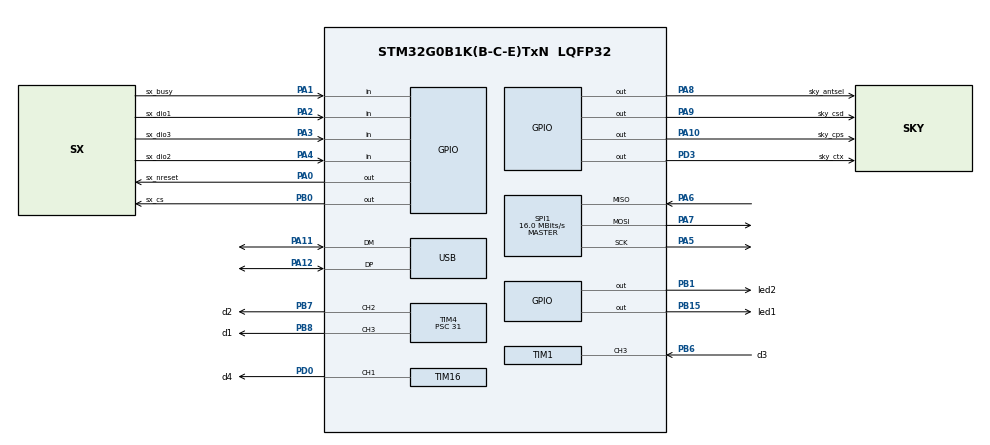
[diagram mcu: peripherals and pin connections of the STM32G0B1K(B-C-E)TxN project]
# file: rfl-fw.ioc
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IWDG.Prescaler=IWDG_PRESCALER_32
IWDG.Reload=1000
IWDG.Window=1000
Mcu.Family=STM32G0
Mcu.Name=STM32G0B1K(B-C-E)TxN
Mcu.Package=LQFP32
NVIC.TIM1_CC_IRQn=true\:0\:0\:false\:false\:false\:true\:true\:true
NVIC.USB_UCPD1_2_IRQn=true\:0\:0\:false\:false\:true\:true\:true\:true
PA0.GPIO_Label=sx_nreset
PA0.Signal=GPIO_Output
PA1.GPIO_Label=sx_busy
PA1.Signal=GPIO_Input
PA10.GPIO_Label=sky_cps
PA10.Signal=GPIO_Output
PA11\ [PA9].Mode=Device
PA11\ [PA9].Signal=USB_DM
PA12\ [PA10].Mode=Device
PA12\ [PA10].Signal=USB_DP
PA13.Mode=Serial_Wire
PA13.Signal=SYS_SWDIO
PA14-BOOT0.Mode=Serial_Wire
PA14-BOOT0.Signal=SYS_SWCLK
PA2.GPIO_Label=sx_dio1
PA2.Signal=GPIO_Input
PA3.GPIO_Label=sx_dio3
PA3.Signal=GPIO_Input
PA4.GPIO_Label=sx_dio2
PA4.Signal=GPIO_Input
PA5.Mode=Full_Duplex_Master
PA5.Signal=SPI1_SCK
PA6.Mode=Full_Duplex_Master
PA6.Signal=SPI1_MISO
PA7.Mode=Full_Duplex_Master
PA7.Signal=SPI1_MOSI
PA8.GPIO_Label=sky_antsel
PA8.Signal=GPIO_Output
PA9.GPIO_Label=sky_csd
PA9.Signal=GPIO_Output
PB0.GPIO_Label=sx_cs
PB0.Signal=GPIO_Output
PB1.GPIO_Label=led2
PB1.Signal=GPIO_Output
PB15.GPIO_Label=led1
PB15.Signal=GPIO_Output
PB6.GPIO_Label=d3
PB6.GPIO_PuPd=GPIO_PULLUP
PB6.Signal=S_TIM1_CH3
PB7.GPIO_Label=d2
PB7.Signal=S_TIM4_CH2
PB8.GPIO_Label=d1
PB8.Signal=S_TIM4_CH3
PD0.GPIO_Label=d4
PD0.Signal=S_TIM16_CH1
PD3.GPIO_Label=sky_ctx
PD3.Signal=GPIO_Output
ProjectManager.HeapSize=0x200
ProjectManager.StackSize=0x400
ProjectManager.TargetToolchain=STM32CubeIDE
RCC.ADCFreq_Value=32000000
RCC.AHBFreq_Value=32000000
RCC.CortexFreq_Value=32000000
RCC.EXTERNAL_CLOCK_VALUE=48000
RCC.HCLKFreq_Value=32000000
RCC.HSE_VALUE=8000000
RCC.HSI48_VALUE=48000000
RCC.HSI_VALUE=16000000
RCC.LSE_VALUE=32768
RCC.PLLR=RCC_PLLR_DIV4
RCC.SYSCLKFreq_VALUE=32000000
RCC.SYSCLKSource=RCC_SYSCLKSOURCE_PLLCLK
RCC.USBFreq_Value=48000000
RCC.VCOOutputFreq_Value=128000000
SH.S_TIM16_CH1.0=TIM16_CH1,PWM Generation1 CH1
SH.S_TIM1_CH3.0=TIM1_CH3,Input_Capture3_from_TI3
SH.S_TIM4_CH2.0=TIM4_CH2,PWM Generation2 CH2
SH.S_TIM4_CH3.0=TIM4_CH3,PWM Generation3 CH3
SPI1.CalculateBaudRate=16.0 MBits/s
SPI1.Direction=SPI_DIRECTION_2LINES
SPI1.Mode=SPI_MODE_MASTER
SPI1.VirtualType=VM_MASTER
TIM1.Channel-Input_Capture3_from_TI3=TIM_CHANNEL_3
TIM1.ICFilter_CH3=4
TIM1.Period=0xffff
TIM1.Prescaler=31
TIM16.AutomaticOutput=TIM_AUTOMATICOUTPUT_ENABLE
TIM16.Channel=TIM_CHANNEL_1
TIM16.Period=20000
TIM16.Prescaler=31
TIM4.Channel-PWM\ Generation2\ CH2=TIM_CHANNEL_2
TIM4.Channel-PWM\ Generation3\ CH3=TIM_CHANNEL_3
TIM4.Period=20000
TIM4.Prescaler=31
USB_DEVICE.CLASS_NAME_FS=CDC
USB_DEVICE.PRODUCT_STRING_CDC_FS=rfl
USB_DEVICE.VirtualMode=Cdc
USB_DEVICE.VirtualModeFS=Cdc_FS
VP_IWDG_VS_IWDG.Mode=IWDG_Activate
VP_SYS_VS_DBSignals.Mode=DisableDeadBatterySignals
VP_TIM16_VS_ClockSourceINT.Mode=Enable_Timer
VP_TIM1_VS_ClockSourceINT.Mode=Internal
VP_TIM4_VS_ClockSourceINT.Mode=Internal
VP_USB_DEVICE_VS_USB_DEVICE_CDC_FS.Mode=CDC_FS
board=custom

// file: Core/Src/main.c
/* USER CODE BEGIN Header */
/**
  ******************************************************************************
  * @file           : main.c
  * @brief          : Main program body
  ******************************************************************************
  * @attention
  *
  * Copyright (c) 2026 STMicroelectronics.
  * All rights reserved.
  *
  * This software is licensed under terms that can be found in the LICENSE file
  * in the root directory of this software component.
  * If no LICENSE file comes with this software, it is provided AS-IS.
  *
  ******************************************************************************
  */
/* USER CODE END Header */
#include "main.h"
#include "usb_device.h"

void SystemClock_Config(void);
static void MX_GPIO_Init(void);
static void MX_SPI1_Init(void);
static void MX_TIM1_Init(void);
static void MX_TIM4_Init(void);
static void MX_TIM16_Init(void);
static void MX_IWDG_Init(void);

/* USER CODE BEGIN 0 */
void init()
{
  HAL_Init();
  SystemClock_Config();

  MX_GPIO_Init();
  MX_SPI1_Init();
  MX_TIM1_Init();
  MX_TIM4_Init();
  MX_TIM16_Init();
  MX_IWDG_Init();
  MX_USB_Device_Init();
}
/* USER CODE END 0 */

void SystemClock_Config(void)
{
  LL_FLASH_SetLatency(LL_FLASH_LATENCY_1);
  while(LL_FLASH_GetLatency() != LL_FLASH_LATENCY_1)
  {
  }

  /* HSI configuration and activation */
  LL_RCC_HSI_Enable();
  while(LL_RCC_HSI_IsReady() != 1)
  {
  }

  /* LSI configuration and activation */
  LL_RCC_LSI_Enable();
  while(LL_RCC_LSI_IsReady() != 1)
  {
  }

  LL_RCC_HSI48_Enable();

   /* Wait till HSI48 is ready */
  while(LL_RCC_HSI48_IsReady() != 1)
  {
  }

  /* Main PLL configuration and activation */
  LL_RCC_PLL_ConfigDomain_SYS(LL_RCC_PLLSOURCE_HSI, LL_RCC_PLLM_DIV_1, 8, LL_RCC_PLLR_DIV_4);
  LL_RCC_PLL_Enable();
  LL_RCC_PLL_EnableDomain_SYS();
  while(LL_RCC_PLL_IsReady() != 1)
  {
  }

  /* Set AHB prescaler*/
  LL_RCC_SetAHBPrescaler(LL_RCC_SYSCLK_DIV_1);

  /* Sysclk activation on the main PLL */
  LL_RCC_SetSysClkSource(LL_RCC_SYS_CLKSOURCE_PLL);
  while(LL_RCC_GetSysClkSource() != LL_RCC_SYS_CLKSOURCE_STATUS_PLL)
  {
  }

  /* Set APB1 prescaler*/
  LL_RCC_SetAPB1Prescaler(LL_RCC_APB1_DIV_1);
  /* Update CMSIS variable (which can be updated also through SystemCoreClockUpdate function) */
  LL_SetSystemCoreClock(32000000);

   /* Update the time base */
  if (HAL_InitTick (TICK_INT_PRIORITY) != HAL_OK)
  {
    Error_Handler();
  }
}

static void MX_IWDG_Init(void)
{

  LL_IWDG_Enable(IWDG);
  LL_IWDG_EnableWriteAccess(IWDG);
  LL_IWDG_SetPrescaler(IWDG, LL_IWDG_PRESCALER_32);
  LL_IWDG_SetReloadCounter(IWDG, 1000);
  while (LL_IWDG_IsReady(IWDG) != 1)
  {
  }

  LL_IWDG_SetWindow(IWDG, 1000);

}

static void MX_SPI1_Init(void)
{

  LL_SPI_InitTypeDef SPI_InitStruct = {0};

  LL_GPIO_InitTypeDef GPIO_InitStruct = {0};

  /* Peripheral clock enable */
  LL_APB2_GRP1_EnableClock(LL_APB2_GRP1_PERIPH_SPI1);

  LL_IOP_GRP1_EnableClock(LL_IOP_GRP1_PERIPH_GPIOA);
  /**SPI1 GPIO Configuration
  PA5   ------> SPI1_SCK
  PA6   ------> SPI1_MISO
  PA7   ------> SPI1_MOSI
  */
  GPIO_InitStruct.Pin = LL_GPIO_PIN_5;
  GPIO_InitStruct.Mode = LL_GPIO_MODE_ALTERNATE;
  GPIO_InitStruct.Speed = LL_GPIO_SPEED_FREQ_LOW;
  GPIO_InitStruct.OutputType = LL_GPIO_OUTPUT_PUSHPULL;
  GPIO_InitStruct.Pull = LL_GPIO_PULL_NO;
  GPIO_InitStruct.Alternate = LL_GPIO_AF_0;
  LL_GPIO_Init(GPIOA, &GPIO_InitStruct);

  GPIO_InitStruct.Pin = LL_GPIO_PIN_6;
  GPIO_InitStruct.Mode = LL_GPIO_MODE_ALTERNATE;
  GPIO_InitStruct.Speed = LL_GPIO_SPEED_FREQ_LOW;
  GPIO_InitStruct.OutputType = LL_GPIO_OUTPUT_PUSHPULL;
  GPIO_InitStruct.Pull = LL_GPIO_PULL_NO;
  GPIO_InitStruct.Alternate = LL_GPIO_AF_0;
  LL_GPIO_Init(GPIOA, &GPIO_InitStruct);

  GPIO_InitStruct.Pin = LL_GPIO_PIN_7;
  GPIO_InitStruct.Mode = LL_GPIO_MODE_ALTERNATE;
  GPIO_InitStruct.Speed = LL_GPIO_SPEED_FREQ_LOW;
  GPIO_InitStruct.OutputType = LL_GPIO_OUTPUT_PUSHPULL;
  GPIO_InitStruct.Pull = LL_GPIO_PULL_NO;
  GPIO_InitStruct.Alternate = LL_GPIO_AF_0;
  LL_GPIO_Init(GPIOA, &GPIO_InitStruct);

  /* SPI1 parameter configuration*/
  SPI_InitStruct.TransferDirection = LL_SPI_FULL_DUPLEX;
  SPI_InitStruct.Mode = LL_SPI_MODE_MASTER;
  SPI_InitStruct.DataWidth = LL_SPI_DATAWIDTH_8BIT;
  SPI_InitStruct.ClockPolarity = LL_SPI_POLARITY_LOW;
  SPI_InitStruct.ClockPhase = LL_SPI_PHASE_1EDGE;
  SPI_InitStruct.NSS = LL_SPI_NSS_SOFT;
  SPI_InitStruct.BaudRate = LL_SPI_BAUDRATEPRESCALER_DIV2;
  SPI_InitStruct.BitOrder = LL_SPI_MSB_FIRST;
  SPI_InitStruct.CRCCalculation = LL_SPI_CRCCALCULATION_DISABLE;
  SPI_InitStruct.CRCPoly = 7;
  LL_SPI_Init(SPI1, &SPI_InitStruct);
  LL_SPI_SetStandard(SPI1, LL_SPI_PROTOCOL_MOTOROLA);
  LL_SPI_EnableNSSPulseMgt(SPI1);

}

static void MX_TIM1_Init(void)
{

  LL_TIM_InitTypeDef TIM_InitStruct = {0};

  LL_GPIO_InitTypeDef GPIO_InitStruct = {0};

  LL_RCC_SetTIMClockSource(LL_RCC_TIM1_CLKSOURCE_PCLK1);

  /* Peripheral clock enable */
  LL_APB2_GRP1_EnableClock(LL_APB2_GRP1_PERIPH_TIM1);

  LL_IOP_GRP1_EnableClock(LL_IOP_GRP1_PERIPH_GPIOB);
  /**TIM1 GPIO Configuration
  PB6   ------> TIM1_CH3
  */
  GPIO_InitStruct.Pin = d3_Pin;
  GPIO_InitStruct.Mode = LL_GPIO_MODE_ALTERNATE;
  GPIO_InitStruct.Speed = LL_GPIO_SPEED_FREQ_LOW;
  GPIO_InitStruct.OutputType = LL_GPIO_OUTPUT_PUSHPULL;
  GPIO_InitStruct.Pull = LL_GPIO_PULL_UP;
  GPIO_InitStruct.Alternate = LL_GPIO_AF_1;
  LL_GPIO_Init(d3_GPIO_Port, &GPIO_InitStruct);

  /* TIM1 interrupt Init */
  NVIC_SetPriority(TIM1_CC_IRQn, 0);
  NVIC_EnableIRQ(TIM1_CC_IRQn);

  TIM_InitStruct.Prescaler = 31;
  TIM_InitStruct.CounterMode = LL_TIM_COUNTERMODE_UP;
  TIM_InitStruct.Autoreload = 0xffff;
  TIM_InitStruct.ClockDivision = LL_TIM_CLOCKDIVISION_DIV1;
  TIM_InitStruct.RepetitionCounter = 0;
  LL_TIM_Init(TIM1, &TIM_InitStruct);
  LL_TIM_DisableARRPreload(TIM1);
  LL_TIM_SetClockSource(TIM1, LL_TIM_CLOCKSOURCE_INTERNAL);
  LL_TIM_SetTriggerOutput(TIM1, LL_TIM_TRGO_RESET);
  LL_TIM_SetTriggerOutput2(TIM1, LL_TIM_TRGO2_RESET);
  LL_TIM_DisableMasterSlaveMode(TIM1);
  LL_TIM_IC_SetActiveInput(TIM1, LL_TIM_CHANNEL_CH3, LL_TIM_ACTIVEINPUT_DIRECTTI);
  LL_TIM_IC_SetPrescaler(TIM1, LL_TIM_CHANNEL_CH3, LL_TIM_ICPSC_DIV1);
  LL_TIM_IC_SetFilter(TIM1, LL_TIM_CHANNEL_CH3, LL_TIM_IC_FILTER_FDIV2_N6);
  LL_TIM_IC_SetPolarity(TIM1, LL_TIM_CHANNEL_CH3, LL_TIM_IC_POLARITY_RISING);

}

static void MX_TIM4_Init(void)
{

  LL_TIM_InitTypeDef TIM_InitStruct = {0};
  LL_TIM_OC_InitTypeDef TIM_OC_InitStruct = {0};

  LL_GPIO_InitTypeDef GPIO_InitStruct = {0};

  /* Peripheral clock enable */
  LL_APB1_GRP1_EnableClock(LL_APB1_GRP1_PERIPH_TIM4);

  TIM_InitStruct.Prescaler = 31;
  TIM_InitStruct.CounterMode = LL_TIM_COUNTERMODE_UP;
  TIM_InitStruct.Autoreload = 20000;
  TIM_InitStruct.ClockDivision = LL_TIM_CLOCKDIVISION_DIV1;
  LL_TIM_Init(TIM4, &TIM_InitStruct);
  LL_TIM_DisableARRPreload(TIM4);
  LL_TIM_SetClockSource(TIM4, LL_TIM_CLOCKSOURCE_INTERNAL);
  LL_TIM_OC_EnablePreload(TIM4, LL_TIM_CHANNEL_CH2);
  TIM_OC_InitStruct.OCMode = LL_TIM_OCMODE_PWM1;
  TIM_OC_InitStruct.OCState = LL_TIM_OCSTATE_DISABLE;
  TIM_OC_InitStruct.OCNState = LL_TIM_OCSTATE_DISABLE;
  TIM_OC_InitStruct.CompareValue = 0;
  TIM_OC_InitStruct.OCPolarity = LL_TIM_OCPOLARITY_HIGH;
  LL_TIM_OC_Init(TIM4, LL_TIM_CHANNEL_CH2, &TIM_OC_InitStruct);
  LL_TIM_OC_DisableFast(TIM4, LL_TIM_CHANNEL_CH2);
  LL_TIM_OC_EnablePreload(TIM4, LL_TIM_CHANNEL_CH3);
  LL_TIM_OC_Init(TIM4, LL_TIM_CHANNEL_CH3, &TIM_OC_InitStruct);
  LL_TIM_OC_DisableFast(TIM4, LL_TIM_CHANNEL_CH3);
  LL_TIM_SetTriggerOutput(TIM4, LL_TIM_TRGO_RESET);
  LL_TIM_DisableMasterSlaveMode(TIM4);
  LL_IOP_GRP1_EnableClock(LL_IOP_GRP1_PERIPH_GPIOB);
  /**TIM4 GPIO Configuration
  PB7   ------> TIM4_CH2
  PB8   ------> TIM4_CH3
  */
  GPIO_InitStruct.Pin = d2_Pin;
  GPIO_InitStruct.Mode = LL_GPIO_MODE_ALTERNATE;
  GPIO_InitStruct.Speed = LL_GPIO_SPEED_FREQ_LOW;
  GPIO_InitStruct.OutputType = LL_GPIO_OUTPUT_PUSHPULL;
  GPIO_InitStruct.Pull = LL_GPIO_PULL_NO;
  GPIO_InitStruct.Alternate = LL_GPIO_AF_9;
  LL_GPIO_Init(d2_GPIO_Port, &GPIO_InitStruct);

  GPIO_InitStruct.Pin = d1_Pin;
  GPIO_InitStruct.Mode = LL_GPIO_MODE_ALTERNATE;
  GPIO_InitStruct.Speed = LL_GPIO_SPEED_FREQ_LOW;
  GPIO_InitStruct.OutputType = LL_GPIO_OUTPUT_PUSHPULL;
  GPIO_InitStruct.Pull = LL_GPIO_PULL_NO;
  GPIO_InitStruct.Alternate = LL_GPIO_AF_9;
  LL_GPIO_Init(d1_GPIO_Port, &GPIO_InitStruct);

}

static void MX_TIM16_Init(void)
{

  LL_TIM_InitTypeDef TIM_InitStruct = {0};
  LL_TIM_OC_InitTypeDef TIM_OC_InitStruct = {0};
  LL_TIM_BDTR_InitTypeDef TIM_BDTRInitStruct = {0};

  LL_GPIO_InitTypeDef GPIO_InitStruct = {0};

  /* Peripheral clock enable */
  LL_APB2_GRP1_EnableClock(LL_APB2_GRP1_PERIPH_TIM16);

  TIM_InitStruct.Prescaler = 31;
  TIM_InitStruct.CounterMode = LL_TIM_COUNTERMODE_UP;
  TIM_InitStruct.Autoreload = 20000;
  TIM_InitStruct.ClockDivision = LL_TIM_CLOCKDIVISION_DIV1;
  TIM_InitStruct.RepetitionCounter = 0;
  LL_TIM_Init(TIM16, &TIM_InitStruct);
  LL_TIM_DisableARRPreload(TIM16);
  LL_TIM_OC_EnablePreload(TIM16, LL_TIM_CHANNEL_CH1);
  TIM_OC_InitStruct.OCMode = LL_TIM_OCMODE_PWM1;
  TIM_OC_InitStruct.OCState = LL_TIM_OCSTATE_DISABLE;
  TIM_OC_InitStruct.OCNState = LL_TIM_OCSTATE_DISABLE;
  TIM_OC_InitStruct.CompareValue = 0;
  TIM_OC_InitStruct.OCPolarity = LL_TIM_OCPOLARITY_HIGH;
  TIM_OC_InitStruct.OCNPolarity = LL_TIM_OCPOLARITY_HIGH;
  TIM_OC_InitStruct.OCIdleState = LL_TIM_OCIDLESTATE_LOW;
  TIM_OC_InitStruct.OCNIdleState = LL_TIM_OCIDLESTATE_LOW;
  LL_TIM_OC_Init(TIM16, LL_TIM_CHANNEL_CH1, &TIM_OC_InitStruct);
  LL_TIM_OC_DisableFast(TIM16, LL_TIM_CHANNEL_CH1);
  TIM_BDTRInitStruct.OSSRState = LL_TIM_OSSR_DISABLE;
  TIM_BDTRInitStruct.OSSIState = LL_TIM_OSSI_DISABLE;
  TIM_BDTRInitStruct.LockLevel = LL_TIM_LOCKLEVEL_OFF;
  TIM_BDTRInitStruct.DeadTime = 0;
  TIM_BDTRInitStruct.BreakState = LL_TIM_BREAK_DISABLE;
  TIM_BDTRInitStruct.BreakPolarity = LL_TIM_BREAK_POLARITY_HIGH;
  TIM_BDTRInitStruct.BreakFilter = LL_TIM_BREAK_FILTER_FDIV1;
  TIM_BDTRInitStruct.AutomaticOutput = LL_TIM_AUTOMATICOUTPUT_ENABLE;
  LL_TIM_BDTR_Init(TIM16, &TIM_BDTRInitStruct);
  LL_IOP_GRP1_EnableClock(LL_IOP_GRP1_PERIPH_GPIOD);
  /**TIM16 GPIO Configuration
  PD0   ------> TIM16_CH1
  */
  GPIO_InitStruct.Pin = d4_Pin;
  GPIO_InitStruct.Mode = LL_GPIO_MODE_ALTERNATE;
  GPIO_InitStruct.Speed = LL_GPIO_SPEED_FREQ_LOW;
  GPIO_InitStruct.OutputType = LL_GPIO_OUTPUT_PUSHPULL;
  GPIO_InitStruct.Pull = LL_GPIO_PULL_NO;
  GPIO_InitStruct.Alternate = LL_GPIO_AF_2;
  LL_GPIO_Init(d4_GPIO_Port, &GPIO_InitStruct);

}

static void MX_GPIO_Init(void)
{
  LL_GPIO_InitTypeDef GPIO_InitStruct = {0};

  /* GPIO Ports Clock Enable */
  LL_IOP_GRP1_EnableClock(LL_IOP_GRP1_PERIPH_GPIOA);
  LL_IOP_GRP1_EnableClock(LL_IOP_GRP1_PERIPH_GPIOB);
  LL_IOP_GRP1_EnableClock(LL_IOP_GRP1_PERIPH_GPIOD);

  /**/
  LL_GPIO_ResetOutputPin(sx_nreset_GPIO_Port, sx_nreset_Pin);

  /**/
  LL_GPIO_ResetOutputPin(sx_cs_GPIO_Port, sx_cs_Pin);

  /**/
  LL_GPIO_ResetOutputPin(led2_GPIO_Port, led2_Pin);

  /**/
  LL_GPIO_ResetOutputPin(led1_GPIO_Port, led1_Pin);

  /**/
  LL_GPIO_ResetOutputPin(sky_antsel_GPIO_Port, sky_antsel_Pin);

  /**/
  LL_GPIO_ResetOutputPin(sky_csd_GPIO_Port, sky_csd_Pin);

  /**/
  LL_GPIO_ResetOutputPin(sky_cps_GPIO_Port, sky_cps_Pin);

  /**/
  LL_GPIO_ResetOutputPin(sky_ctx_GPIO_Port, sky_ctx_Pin);

  /**/
  GPIO_InitStruct.Pin = sx_nreset_Pin;
  GPIO_InitStruct.Mode = LL_GPIO_MODE_OUTPUT;
  GPIO_InitStruct.Speed = LL_GPIO_SPEED_FREQ_LOW;
  GPIO_InitStruct.OutputType = LL_GPIO_OUTPUT_PUSHPULL;
  GPIO_InitStruct.Pull = LL_GPIO_PULL_NO;
  LL_GPIO_Init(sx_nreset_GPIO_Port, &GPIO_InitStruct);

  /**/
  GPIO_InitStruct.Pin = sx_busy_Pin;
  GPIO_InitStruct.Mode = LL_GPIO_MODE_INPUT;
  GPIO_InitStruct.Pull = LL_GPIO_PULL_NO;
  LL_GPIO_Init(sx_busy_GPIO_Port, &GPIO_InitStruct);

  /**/
  GPIO_InitStruct.Pin = sx_dio1_Pin;
  GPIO_InitStruct.Mode = LL_GPIO_MODE_INPUT;
  GPIO_InitStruct.Pull = LL_GPIO_PULL_NO;
  LL_GPIO_Init(sx_dio1_GPIO_Port, &GPIO_InitStruct);

  /**/
  GPIO_InitStruct.Pin = sx_dio3_Pin;
  GPIO_InitStruct.Mode = LL_GPIO_MODE_INPUT;
  GPIO_InitStruct.Pull = LL_GPIO_PULL_NO;
  LL_GPIO_Init(sx_dio3_GPIO_Port, &GPIO_InitStruct);

  /**/
  GPIO_InitStruct.Pin = sx_dio2_Pin;
  GPIO_InitStruct.Mode = LL_GPIO_MODE_INPUT;
  GPIO_InitStruct.Pull = LL_GPIO_PULL_NO;
  LL_GPIO_Init(sx_dio2_GPIO_Port, &GPIO_InitStruct);

  /**/
  GPIO_InitStruct.Pin = sx_cs_Pin;
  GPIO_InitStruct.Mode = LL_GPIO_MODE_OUTPUT;
  GPIO_InitStruct.Speed = LL_GPIO_SPEED_FREQ_LOW;
  GPIO_InitStruct.OutputType = LL_GPIO_OUTPUT_PUSHPULL;
  GPIO_InitStruct.Pull = LL_GPIO_PULL_NO;
  LL_GPIO_Init(sx_cs_GPIO_Port, &GPIO_InitStruct);

  /**/
  GPIO_InitStruct.Pin = led2_Pin;
  GPIO_InitStruct.Mode = LL_GPIO_MODE_OUTPUT;
  GPIO_InitStruct.Speed = LL_GPIO_SPEED_FREQ_LOW;
  GPIO_InitStruct.OutputType = LL_GPIO_OUTPUT_PUSHPULL;
  GPIO_InitStruct.Pull = LL_GPIO_PULL_NO;
  LL_GPIO_Init(led2_GPIO_Port, &GPIO_InitStruct);

  /**/
  GPIO_InitStruct.Pin = led1_Pin;
  GPIO_InitStruct.Mode = LL_GPIO_MODE_OUTPUT;
  GPIO_InitStruct.Speed = LL_GPIO_SPEED_FREQ_LOW;
  GPIO_InitStruct.OutputType = LL_GPIO_OUTPUT_PUSHPULL;
  GPIO_InitStruct.Pull = LL_GPIO_PULL_NO;
  LL_GPIO_Init(led1_GPIO_Port, &GPIO_InitStruct);

  /**/
  GPIO_InitStruct.Pin = sky_antsel_Pin;
  GPIO_InitStruct.Mode = LL_GPIO_MODE_OUTPUT;
  GPIO_InitStruct.Speed = LL_GPIO_SPEED_FREQ_LOW;
  GPIO_InitStruct.OutputType = LL_GPIO_OUTPUT_PUSHPULL;
  GPIO_InitStruct.Pull = LL_GPIO_PULL_NO;
  LL_GPIO_Init(sky_antsel_GPIO_Port, &GPIO_InitStruct);

  /**/
  GPIO_InitStruct.Pin = sky_csd_Pin;
  GPIO_InitStruct.Mode = LL_GPIO_MODE_OUTPUT;
  GPIO_InitStruct.Speed = LL_GPIO_SPEED_FREQ_LOW;
  GPIO_InitStruct.OutputType = LL_GPIO_OUTPUT_PUSHPULL;
  GPIO_InitStruct.Pull = LL_GPIO_PULL_NO;
  LL_GPIO_Init(sky_csd_GPIO_Port, &GPIO_InitStruct);

  /**/
  GPIO_InitStruct.Pin = sky_cps_Pin;
  GPIO_InitStruct.Mode = LL_GPIO_MODE_OUTPUT;
  GPIO_InitStruct.Speed = LL_GPIO_SPEED_FREQ_LOW;
  GPIO_InitStruct.OutputType = LL_GPIO_OUTPUT_PUSHPULL;
  GPIO_InitStruct.Pull = LL_GPIO_PULL_NO;
  LL_GPIO_Init(sky_cps_GPIO_Port, &GPIO_InitStruct);

  /**/
  GPIO_InitStruct.Pin = sky_ctx_Pin;
  GPIO_InitStruct.Mode = LL_GPIO_MODE_OUTPUT;
  GPIO_InitStruct.Speed = LL_GPIO_SPEED_FREQ_LOW;
  GPIO_InitStruct.OutputType = LL_GPIO_OUTPUT_PUSHPULL;
  GPIO_InitStruct.Pull = LL_GPIO_PULL_NO;
  LL_GPIO_Init(sky_ctx_GPIO_Port, &GPIO_InitStruct);

}

void Error_Handler(void)
{
  __disable_irq();
  while (1)
  {
  }
}
